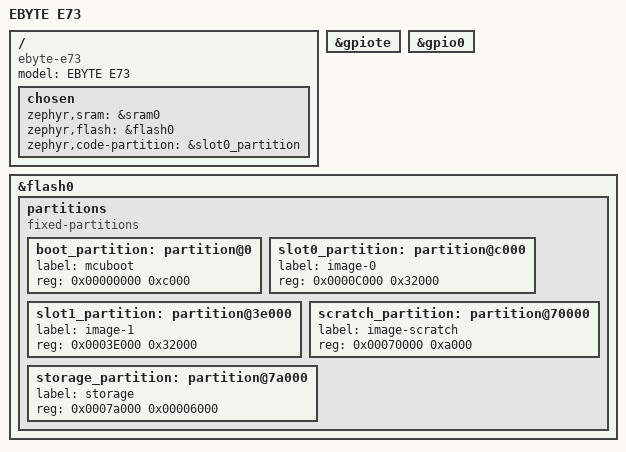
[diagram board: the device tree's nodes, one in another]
/*
 * Copyright (c) 2018 Zelin <zelin@makerdiary.com>
 * Copyright (c) 2018 makerdiary.com.
 *
 * SPDX-License-Identifier: Apache-2.0
 */

/dts-v1/;
#include <nordic/nrf52832_qfaa.dtsi>

/ {
	model = "EBYTE E73";
	compatible = "ebyte-e73";

	chosen {
		zephyr,sram = &sram0;
		zephyr,flash = &flash0;
		zephyr,code-partition = &slot0_partition;
	};
};

&gpiote {
	status = "okay";
};

&gpio0 {
	status = "okay";
};

&flash0 {
	/*
	 * For more information, see:
	 * http://docs.zephyrproject.org/latest/guides/dts/index.html#flash-partitions
	 */
	partitions {
		compatible = "fixed-partitions";
		#address-cells = <1>;
		#size-cells = <1>;

		boot_partition: partition@0 {
			label = "mcuboot";
			reg = <0x00000000 0xc000>;
		};
		slot0_partition: partition@c000 {
			label = "image-0";
			reg = <0x0000C000 0x32000>;
		};
		slot1_partition: partition@3e000 {
			label = "image-1";
			reg = <0x0003E000 0x32000>;
		};
		scratch_partition: partition@70000 {
			label = "image-scratch";
			reg = <0x00070000 0xa000>;
		};
		storage_partition: partition@7a000 {
			label = "storage";
			reg = <0x0007a000 0x00006000>;
		};
	};
};
